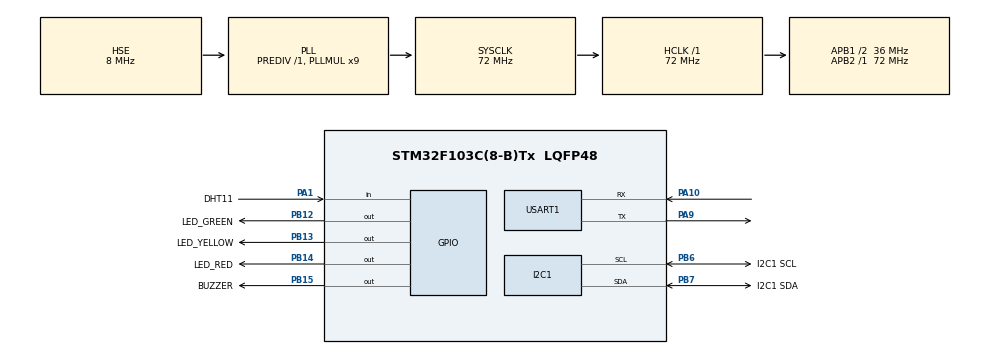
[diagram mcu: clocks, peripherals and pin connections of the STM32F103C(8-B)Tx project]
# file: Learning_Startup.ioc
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Mcu.Family=STM32F1
Mcu.Name=STM32F103C(8-B)Tx
Mcu.Package=LQFP48
NVIC.PriorityGroup=NVIC_PRIORITYGROUP_4
PA1.GPIO_Label=DHT11
PA1.Signal=GPIO_Input
PA10.Mode=Asynchronous
PA10.Signal=USART1_RX
PA13.Mode=Serial_Wire
PA13.Signal=SYS_JTMS-SWDIO
PA14.Mode=Serial_Wire
PA14.Signal=SYS_JTCK-SWCLK
PA9.Mode=Asynchronous
PA9.Signal=USART1_TX
PB12.GPIO_Label=LED_GREEN
PB12.Signal=GPIO_Output
PB13.GPIO_Label=LED_YELLOW
PB13.Signal=GPIO_Output
PB14.GPIO_Label=LED_RED
PB14.Signal=GPIO_Output
PB15.GPIO_Label=BUZZER
PB15.PinState=GPIO_PIN_SET
PB15.Signal=GPIO_Output
PB6.GPIO_Label=I2C1 SCL
PB6.Mode=I2C
PB6.Signal=I2C1_SCL
PB7.GPIO_Label=I2C1 SDA
PB7.Mode=I2C
PB7.Signal=I2C1_SDA
PD0-OSC_IN.Mode=HSE-External-Oscillator
PD0-OSC_IN.Signal=RCC_OSC_IN
PD1-OSC_OUT.Mode=HSE-External-Oscillator
PD1-OSC_OUT.Signal=RCC_OSC_OUT
ProjectManager.HeapSize=0x200
ProjectManager.StackSize=0x400
ProjectManager.TargetToolchain=CMake
RCC.AHBFreq_Value=72000000
RCC.APB1CLKDivider=RCC_HCLK_DIV2
RCC.APB1Freq_Value=36000000
RCC.APB1TimFreq_Value=72000000
RCC.APB2Freq_Value=72000000
RCC.APB2TimFreq_Value=72000000
RCC.HCLKFreq_Value=72000000
RCC.PLLMUL=RCC_PLL_MUL9
RCC.PLLSourceVirtual=RCC_PLLSOURCE_HSE
RCC.SYSCLKFreq_VALUE=72000000
RCC.SYSCLKSource=RCC_SYSCLKSOURCE_PLLCLK
RCC.USBFreq_Value=72000000
TIM1.Prescaler=71
USART1.VirtualMode=VM_ASYNC
VP_TIM1_VS_ClockSourceINT.Mode=Internal
board=custom

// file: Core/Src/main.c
/* USER CODE BEGIN Header */
/**
  ******************************************************************************
  * @file           : main.c
  * @brief          : Main program body
  ******************************************************************************
  * @attention
  *
  * Copyright (c) 2026 STMicroelectronics.
  * All rights reserved.
  *
  * This software is licensed under terms that can be found in the LICENSE file
  * in the root directory of this software component.
  * If no LICENSE file comes with this software, it is provided AS-IS.
  *
  ******************************************************************************
  */
/* USER CODE END Header */

#include "main.h"

/* USER CODE BEGIN Includes */
#include "dht11.h"
#include "fsm.h"
#include "output.h"
#include "lcd.h"
#include "uart_log.h"
/* USER CODE END Includes */

I2C_HandleTypeDef hi2c1;

TIM_HandleTypeDef htim1;

UART_HandleTypeDef huart1;

void SystemClock_Config(void);

static void MX_GPIO_Init(void);
static void MX_I2C1_Init(void);
static void MX_USART1_UART_Init(void);
static void MX_TIM1_Init(void);

int main(void)
{

    /* MCU Configuration------------------------------------------------------*/

    /*
     * Reset of all peripherals,
     * Initializes the Flash interface
     * and the SysTick.
     */
    HAL_Init();

    /*
     * Configure the system clock.
     */
    SystemClock_Config();

    /*
     * Initialize all configured peripherals.
     */
    MX_GPIO_Init();
    MX_I2C1_Init();
    MX_USART1_UART_Init();
    MX_TIM1_Init();

    /* USER CODE BEGIN 2 */

    UART_WriteString(
        "\r\n=== ENVIRONMENT MONITOR START ===\r\n");

    DHT11_Init();

    Output_Init();

    LCD_Init();

    FSM_Init();

    /* USER CODE END 2 */

    /* Infinite loop */
    while (1)
    {

        /* USER CODE BEGIN 3 */

        FSM_Process();

        /* USER CODE END 3 */
    }
}

void SystemClock_Config(void)
{
    RCC_OscInitTypeDef RCC_OscInitStruct = {0};
    RCC_ClkInitTypeDef RCC_ClkInitStruct = {0};

    /*
     * Initializes the RCC Oscillators
     * according to the specified parameters.
     */
    RCC_OscInitStruct.OscillatorType =
        RCC_OSCILLATORTYPE_HSE;

    RCC_OscInitStruct.HSEState =
        RCC_HSE_ON;

    RCC_OscInitStruct.HSEPredivValue =
        RCC_HSE_PREDIV_DIV1;

    RCC_OscInitStruct.HSIState =
        RCC_HSI_ON;

    RCC_OscInitStruct.PLL.PLLState =
        RCC_PLL_ON;

    RCC_OscInitStruct.PLL.PLLSource =
        RCC_PLLSOURCE_HSE;

    RCC_OscInitStruct.PLL.PLLMUL =
        RCC_PLL_MUL9;

    if (HAL_RCC_OscConfig(
            &RCC_OscInitStruct) != HAL_OK)
    {
        Error_Handler();
    }

    /*
     * Initializes CPU, AHB and APB clocks.
     */
    RCC_ClkInitStruct.ClockType =
        RCC_CLOCKTYPE_HCLK |
        RCC_CLOCKTYPE_SYSCLK |
        RCC_CLOCKTYPE_PCLK1 |
        RCC_CLOCKTYPE_PCLK2;

    RCC_ClkInitStruct.SYSCLKSource =
        RCC_SYSCLKSOURCE_PLLCLK;

    RCC_ClkInitStruct.AHBCLKDivider =
        RCC_SYSCLK_DIV1;

    RCC_ClkInitStruct.APB1CLKDivider =
        RCC_HCLK_DIV2;

    RCC_ClkInitStruct.APB2CLKDivider =
        RCC_HCLK_DIV1;

    if (HAL_RCC_ClockConfig(
            &RCC_ClkInitStruct,
            FLASH_LATENCY_2) != HAL_OK)
    {
        Error_Handler();
    }
}

static void MX_I2C1_Init(void)
{

    hi2c1.Instance =
        I2C1;

    hi2c1.Init.ClockSpeed =
        100000;

    hi2c1.Init.DutyCycle =
        I2C_DUTYCYCLE_2;

    hi2c1.Init.OwnAddress1 =
        0;

    hi2c1.Init.AddressingMode =
        I2C_ADDRESSINGMODE_7BIT;

    hi2c1.Init.DualAddressMode =
        I2C_DUALADDRESS_DISABLE;

    hi2c1.Init.OwnAddress2 =
        0;

    hi2c1.Init.GeneralCallMode =
        I2C_GENERALCALL_DISABLE;

    hi2c1.Init.NoStretchMode =
        I2C_NOSTRETCH_DISABLE;

    if (HAL_I2C_Init(
            &hi2c1) != HAL_OK)
    {
        Error_Handler();
    }

}

static void MX_TIM1_Init(void)
{

    TIM_ClockConfigTypeDef
        sClockSourceConfig = {0};

    TIM_MasterConfigTypeDef
        sMasterConfig = {0};

    htim1.Instance =
        TIM1;

    htim1.Init.Prescaler =
        71;

    htim1.Init.CounterMode =
        TIM_COUNTERMODE_UP;

    htim1.Init.Period =
        65535;

    htim1.Init.ClockDivision =
        TIM_CLOCKDIVISION_DIV1;

    htim1.Init.RepetitionCounter =
        0;

    htim1.Init.AutoReloadPreload =
        TIM_AUTORELOAD_PRELOAD_DISABLE;

    if (HAL_TIM_Base_Init(
            &htim1) != HAL_OK)
    {
        Error_Handler();
    }

    sClockSourceConfig.ClockSource =
        TIM_CLOCKSOURCE_INTERNAL;

    if (HAL_TIM_ConfigClockSource(
            &htim1,
            &sClockSourceConfig) != HAL_OK)
    {
        Error_Handler();
    }

    sMasterConfig.MasterOutputTrigger =
        TIM_TRGO_RESET;

    sMasterConfig.MasterSlaveMode =
        TIM_MASTERSLAVEMODE_DISABLE;

    if (HAL_TIMEx_MasterConfigSynchronization(
            &htim1,
            &sMasterConfig) != HAL_OK)
    {
        Error_Handler();
    }

}

static void MX_USART1_UART_Init(void)
{

    huart1.Instance =
        USART1;

    huart1.Init.BaudRate =
        115200;

    huart1.Init.WordLength =
        UART_WORDLENGTH_8B;

    huart1.Init.StopBits =
        UART_STOPBITS_1;

    huart1.Init.Parity =
        UART_PARITY_NONE;

    huart1.Init.Mode =
        UART_MODE_TX_RX;

    huart1.Init.HwFlowCtl =
        UART_HWCONTROL_NONE;

    huart1.Init.OverSampling =
        UART_OVERSAMPLING_16;

    if (HAL_UART_Init(
            &huart1) != HAL_OK)
    {
        Error_Handler();
    }

}

static void MX_GPIO_Init(void)
{
    GPIO_InitTypeDef
        GPIO_InitStruct = {0};

    /*
     * GPIO Ports Clock Enable.
     */
    __HAL_RCC_GPIOD_CLK_ENABLE();
    __HAL_RCC_GPIOA_CLK_ENABLE();
    __HAL_RCC_GPIOB_CLK_ENABLE();

    /*
     * Configure initial LED output levels.
     */
    HAL_GPIO_WritePin(
        GPIOB,
        LED_GREEN_Pin |
        LED_YELLOW_Pin |
        LED_RED_Pin,
        GPIO_PIN_RESET);

    /*
     * Active-low buzzer:
     * HIGH = OFF.
     */
    HAL_GPIO_WritePin(
        BUZZER_GPIO_Port,
        BUZZER_Pin,
        GPIO_PIN_SET);

    /*
     * Configure DHT11 pin.
     */
    GPIO_InitStruct.Pin =
        DHT11_Pin;

    GPIO_InitStruct.Mode =
        GPIO_MODE_INPUT;

    GPIO_InitStruct.Pull =
        GPIO_NOPULL;

    HAL_GPIO_Init(
        DHT11_GPIO_Port,
        &GPIO_InitStruct);

    /*
     * Configure LED and buzzer pins.
     */
    GPIO_InitStruct.Pin =
        LED_GREEN_Pin |
        LED_YELLOW_Pin |
        LED_RED_Pin |
        BUZZER_Pin;

    GPIO_InitStruct.Mode =
        GPIO_MODE_OUTPUT_PP;

    GPIO_InitStruct.Pull =
        GPIO_NOPULL;

    GPIO_InitStruct.Speed =
        GPIO_SPEED_FREQ_LOW;

    HAL_GPIO_Init(
        GPIOB,
        &GPIO_InitStruct);

}

/**
  * @brief  This function is executed
  *         in case of error occurrence.
  * @retval None
  */
void Error_Handler(void)
{
    __disable_irq();
    while (1)
    {
    }
}

#ifdef USE_FULL_ASSERT

/**
  * @brief  Reports the name of the source file
  *         and source line number where
  *         assert_param error occurred.
  * @param  file: pointer to source file name
  * @param  line: source line number
  * @retval None
  */
void assert_failed(
    uint8_t *file,
    uint32_t line)
{
    /* USER CODE BEGIN 6 */

    /*
     * User can add implementation here.
     */

    /* USER CODE END 6 */
}

#endif /* USE_FULL_ASSERT */
